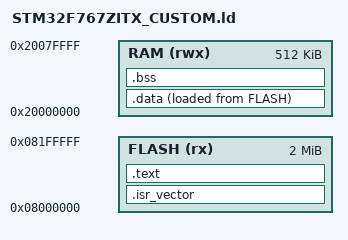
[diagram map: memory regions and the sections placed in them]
ENTRY(Reset_Handler)


MEMORY
{
    RAM  (rwx)   : ORIGIN = 0x20000000, LENGTH = 512K
    FLASH (rx)  : ORIGIN = 0x08000000, LENGTH = 2048K
}

SECTIONS
{
    .isr_vector :
    {
        . = ALIGN(4);
        KEEP(*(.isr_vector))
        . = ALIGN(4);
    } >FLASH

    .text :
    {
        *(.text)
        *(.text.*)
        *(.rodata)
        *(.rodata.*)
        . = ALIGN(4);
        _etext = .;
    } >FLASH

    _la_data = LOADADDR(.data);
    .data :
    {
        _sdata = .;
        *(.data)
        *(.data.*)
        . = ALIGN(4);
        _edata = .;
    } >RAM AT> FLASH

    .bss :
    {
        _sbss = .;
        __bss_start__ = _sbss;
        *(.bss)
        *(.bss.*)
        . = ALIGN(4);
        _ebss = .;
        __bss_end__ = _ebss;
        . = ALIGN(4);
        end = .;
        __end__ = .;
    } >RAM
}
